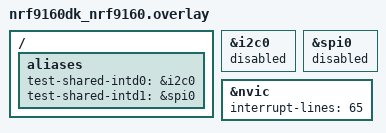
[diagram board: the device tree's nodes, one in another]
/*
 * Copyright (c) 2024 Bjarki Arge Andreasen
 *
 * SPDX-License-Identifier: Apache-2.0
 */

/ {
	aliases {
		test-shared-intd0 = &i2c0;
		test-shared-intd1 = &spi0;
	};
};

&i2c0 {
	status = "reserved";
};

&spi0 {
	status = "reserved";
};

&nvic {
	interrupt-lines = <65>;
};
